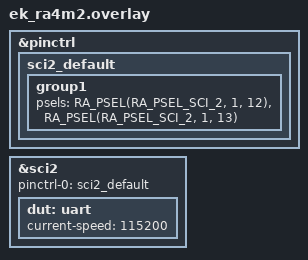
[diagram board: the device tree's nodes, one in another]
/*
 * Copyright (c) 2024 Renesas Electronics Corporation
 * SPDX-License-Identifier: Apache-2.0
 */

&pinctrl {
	sci2_default: sci2_default {
		group1 {
			/* tx rx */
			psels = <RA_PSEL(RA_PSEL_SCI_2, 1, 12)>,
				<RA_PSEL(RA_PSEL_SCI_2, 1, 13)>;
		};
	};
};

&sci2 {
	pinctrl-0 = <&sci2_default>;
	pinctrl-names = "default";
	status = "okay";
	dut: uart {
		current-speed = <115200>;
		status = "okay";
	};
};
